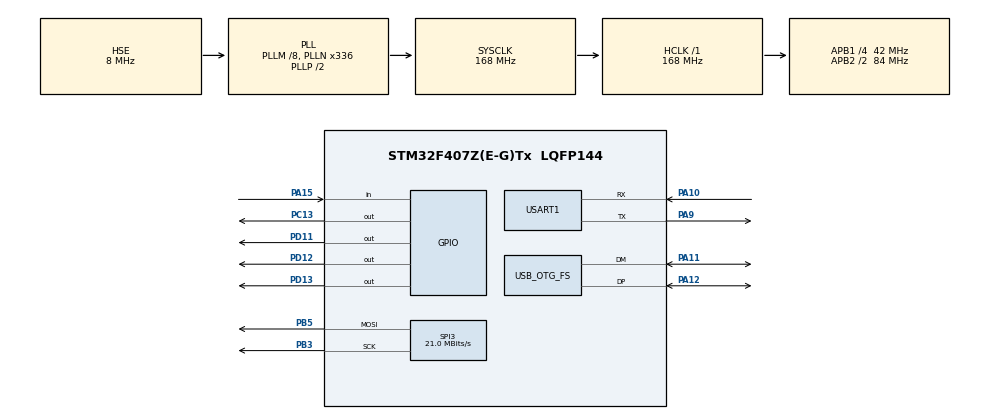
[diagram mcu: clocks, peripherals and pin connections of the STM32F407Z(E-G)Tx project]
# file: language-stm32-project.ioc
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FREERTOS.Tasks01=defaultTask,24,128,StartDefaultTask,Default,NULL,Dynamic,NULL,NULL;myTask02,8,128,StartTask02,Default,NULL,Dynamic,NULL,NULL
Mcu.Family=STM32F4
Mcu.Name=STM32F407Z(E-G)Tx
Mcu.Package=LQFP144
NVIC.OTG_FS_IRQn=true\:5\:0\:false\:false\:true\:true\:false\:true\:true
NVIC.PriorityGroup=NVIC_PRIORITYGROUP_4
NVIC.TIM4_IRQn=true\:15\:0\:false\:false\:true\:false\:false\:true\:true
NVIC.TimeBase=TIM4_IRQn
NVIC.TimeBaseIP=TIM4
NVIC.USART1_IRQn=true\:12\:0\:true\:false\:true\:true\:true\:true\:true
PA10.Mode=Asynchronous
PA10.Signal=USART1_RX
PA11.Mode=Device_Only
PA11.Signal=USB_OTG_FS_DM
PA12.Mode=Device_Only
PA12.Signal=USB_OTG_FS_DP
PA13.Mode=Serial_Wire
PA13.Signal=SYS_JTMS-SWDIO
PA14.Mode=Serial_Wire
PA14.Signal=SYS_JTCK-SWCLK
PA15.GPIO_PuPd=GPIO_PULLUP
PA15.Signal=GPIO_Input
PA9.Mode=Asynchronous
PA9.Signal=USART1_TX
PB3.Mode=TX_Only_Simplex_Unidirect_Master
PB3.Signal=SPI3_SCK
PB5.Mode=TX_Only_Simplex_Unidirect_Master
PB5.Signal=SPI3_MOSI
PC13-ANTI_TAMP.Signal=GPIO_Output
PC14-OSC32_IN.Mode=LSE-External-Oscillator
PC14-OSC32_IN.Signal=RCC_OSC32_IN
PC15-OSC32_OUT.Mode=LSE-External-Oscillator
PC15-OSC32_OUT.Signal=RCC_OSC32_OUT
PD11.Signal=GPIO_Output
PD12.Signal=GPIO_Output
PD13.Signal=GPIO_Output
PH0-OSC_IN.Mode=HSE-External-Oscillator
PH0-OSC_IN.Signal=RCC_OSC_IN
PH1-OSC_OUT.Mode=HSE-External-Oscillator
PH1-OSC_OUT.Signal=RCC_OSC_OUT
ProjectManager.HeapSize=0x600
ProjectManager.StackSize=0x400
ProjectManager.TargetToolchain=CMake
RCC.48MHZClocksFreq_Value=48000000
RCC.AHBFreq_Value=168000000
RCC.APB1CLKDivider=RCC_HCLK_DIV4
RCC.APB1Freq_Value=42000000
RCC.APB1TimFreq_Value=84000000
RCC.APB2CLKDivider=RCC_HCLK_DIV2
RCC.APB2Freq_Value=84000000
RCC.APB2TimFreq_Value=168000000
RCC.CortexFreq_Value=168000000
RCC.HCLKFreq_Value=168000000
RCC.HSE_VALUE=8000000
RCC.HSI_VALUE=16000000
RCC.PLLM=8
RCC.PLLN=336
RCC.PLLQ=7
RCC.RCC_RTC_Clock_Source=RCC_RTCCLKSOURCE_LSE
RCC.RCC_RTC_Clock_SourceVirtual=RCC_RTCCLKSOURCE_LSE
RCC.SYSCLKFreq_VALUE=168000000
RCC.SYSCLKSource=RCC_SYSCLKSOURCE_PLLCLK
RCC.VCOOutputFreq_Value=336000000
SPI3.CRCCalculation=SPI_CRCCALCULATION_DISABLE
SPI3.CalculateBaudRate=21.0 MBits/s
SPI3.Direction=SPI_DIRECTION_2LINES
SPI3.Mode=SPI_MODE_MASTER
SPI3.VirtualType=VM_MASTER
USART1.VirtualMode=VM_ASYNC
USB_DEVICE.CLASS_NAME_FS=HID
USB_DEVICE.VirtualMode-HID_FS=Hid
USB_DEVICE.VirtualModeFS=Hid_FS
USB_OTG_FS.VirtualMode=Device_Only
VP_FREERTOS_VS_CMSIS_V2.Mode=CMSIS_V2
VP_RTC_VS_RTC_Activate.Mode=RTC_Enabled
VP_SYS_VS_tim4.Mode=TIM4
VP_USB_DEVICE_VS_USB_DEVICE_HID_FS.Mode=HID_FS
board=custom

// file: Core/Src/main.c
/* USER CODE BEGIN Header */
/**
  ******************************************************************************
  * @file           : main.c
  * @brief          : Main program body
  ******************************************************************************
  * @attention
  *
  * Copyright (c) 2025 STMicroelectronics.
  * All rights reserved.
  *
  * This software is licensed under terms that can be found in the LICENSE file
  * in the root directory of this software component.
  * If no LICENSE file comes with this software, it is provided AS-IS.
  *
  ******************************************************************************
  */
/* USER CODE END Header */
#include "main.h"
#include "cmsis_os.h"
#include "rtc.h"
#include "spi.h"
#include "usart.h"
#include "usb_device.h"
#include "gpio.h"
// #include "lcd_test.h"
#include "LcdDemo.h"

/* USER CODE BEGIN Includes */

#include "usbd_hid.h"
// #include "stm32_usart.h"

/* USER CODE END Includes */

void SystemClock_Config(void);
void MX_FREERTOS_Init(void);

int main(void)
{

  /* MCU Configuration--------------------------------------------------------*/

  /* Reset of all peripherals, Initializes the Flash interface and the Systick. */
  HAL_Init();

  /* Configure the system clock */
  SystemClock_Config();

  /* Initialize all configured peripherals */
  MX_GPIO_Init();
  MX_USART1_UART_Init();
  MX_SPI3_Init();
  MX_RTC_Init();
  /* USER CODE BEGIN 2 */

  // SPI_LCD_Init();
  /* USER CODE END 2 */

  /* Init scheduler */
  // osKernelInitialize();  /* Call init function for freertos objects (in cmsis_os2.c) */
  // MX_FREERTOS_Init();

  /* Start scheduler */
  // osKernelStart();

  /* We should never get here as control is now taken by the scheduler */

  /* Infinite loop */
  /* USER CODE BEGIN WHILE */
    while (1) {
      // HAL_GPIO_TogglePin(GPIOD, GPIO_PIN_12); // 找一个板子上的 LED 引脚/
      // LCD_Clear();
      // HAL_Delay(22500);
      HAL_Delay(1000);
      HAL_GPIO_TogglePin(GPIOC, GPIO_PIN_13);
      // HAL_GPIO_TogglePin(GPIOD, GPIO_PIN_13);
      //  LCD_Test_Text();
      //  LCD_Test_Variable();
      // HAL_Delay(500);
      //  LCD_Test_Color();
      // HAL_Delay(500);
      //  LCD_Test_Grahic();
      // HAL_Delay(500);
      //  LCD_Test_Image();
      // HAL_Delay(500);
      //  LCD_Test_Direction();
      // HAL_Delay(500);
      //  LCD_Test_Clear();
      // HAL_Delay(500);

    /* USER CODE END WHILE */

    }
}

void SystemClock_Config(void)
{
  RCC_OscInitTypeDef RCC_OscInitStruct = {0};
  RCC_ClkInitTypeDef RCC_ClkInitStruct = {0};

  /** Configure the main internal regulator output voltage
  */
  __HAL_RCC_PWR_CLK_ENABLE();
  __HAL_PWR_VOLTAGESCALING_CONFIG(PWR_REGULATOR_VOLTAGE_SCALE1);

  /** Initializes the RCC Oscillators according to the specified parameters
  * in the RCC_OscInitTypeDef structure.
  */
  RCC_OscInitStruct.OscillatorType = RCC_OSCILLATORTYPE_HSE|RCC_OSCILLATORTYPE_LSE;
  RCC_OscInitStruct.HSEState = RCC_HSE_ON;
  RCC_OscInitStruct.LSEState = RCC_LSE_ON;
  RCC_OscInitStruct.PLL.PLLState = RCC_PLL_ON;
  RCC_OscInitStruct.PLL.PLLSource = RCC_PLLSOURCE_HSE;
  RCC_OscInitStruct.PLL.PLLM = 8;
  RCC_OscInitStruct.PLL.PLLN = 336;
  RCC_OscInitStruct.PLL.PLLP = RCC_PLLP_DIV2;
  RCC_OscInitStruct.PLL.PLLQ = 7;
  if (HAL_RCC_OscConfig(&RCC_OscInitStruct) != HAL_OK)
  {
    Error_Handler();
  }

  /** Initializes the CPU, AHB and APB buses clocks
  */
  RCC_ClkInitStruct.ClockType = RCC_CLOCKTYPE_HCLK|RCC_CLOCKTYPE_SYSCLK
                              |RCC_CLOCKTYPE_PCLK1|RCC_CLOCKTYPE_PCLK2;
  RCC_ClkInitStruct.SYSCLKSource = RCC_SYSCLKSOURCE_PLLCLK;
  RCC_ClkInitStruct.AHBCLKDivider = RCC_SYSCLK_DIV1;
  RCC_ClkInitStruct.APB1CLKDivider = RCC_HCLK_DIV4;
  RCC_ClkInitStruct.APB2CLKDivider = RCC_HCLK_DIV2;

  if (HAL_RCC_ClockConfig(&RCC_ClkInitStruct, FLASH_LATENCY_5) != HAL_OK)
  {
    Error_Handler();
  }
}

/* USER CODE BEGIN 4 */
// void HAL_UART_RxCpltCallback(UART_HandleTypeDef *huart) {
//
//   HAL_UART_Receive_IT( &huart1, )
// }

/* USER CODE END 4 */

void HAL_TIM_PeriodElapsedCallback(TIM_HandleTypeDef *htim)
{
  if (htim->Instance == TIM4)
  {
    HAL_IncTick();
  }
}

void Error_Handler(void)
{
  __disable_irq();
  while (1)
  {
  }
}
